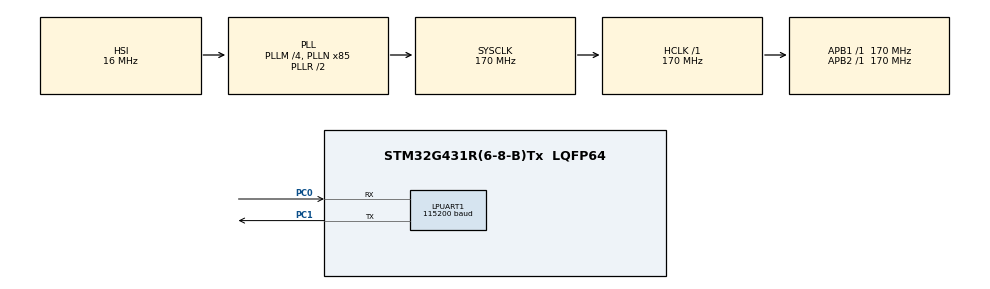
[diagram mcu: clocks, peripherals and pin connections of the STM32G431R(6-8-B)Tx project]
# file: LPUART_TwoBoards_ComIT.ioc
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LPUART1.BaudRate=115200
LPUART1.ClockPrescaler=UART_PRESCALER_DIV1
LPUART1.DMADisableonRxErrorParam=UART_ADVFEATURE_DMA_ENABLEONRXERROR
LPUART1.DataInvertParam=UART_ADVFEATURE_DATAINV_DISABLE
LPUART1.FIFOMode=UART_FIFOMODE_DISABLE
LPUART1.MSBFirstParam=UART_ADVFEATURE_MSBFIRST_DISABLE
LPUART1.Mode=UART_MODE_TX_RX
LPUART1.OneBitSampling=UART_ONE_BIT_SAMPLE_DISABLE
LPUART1.OverrunDisableParam=UART_ADVFEATURE_OVERRUN_ENABLE
LPUART1.Parity=UART_PARITY_NONE
LPUART1.RXFIFOThreshold=UART_RXFIFO_THRESHOLD_1_8
LPUART1.RxPinLevelInvertParam=UART_ADVFEATURE_RXINV_DISABLE
LPUART1.StopBits=UART_STOPBITS_1
LPUART1.SwapParam=UART_ADVFEATURE_SWAP_DISABLE
LPUART1.TXFIFOThreshold=UART_TXFIFO_THRESHOLD_1_8
LPUART1.TxPinLevelInvertParam=UART_ADVFEATURE_TXINV_DISABLE
LPUART1.WordLength=UART_WORDLENGTH_8B
Mcu.Family=STM32G4
Mcu.Name=STM32G431R(6-8-B)Tx
Mcu.Package=LQFP64
NVIC.LPUART1_IRQn=true\:1\:0\:true\:false\:true\:true\:true\:true
NVIC.PriorityGroup=NVIC_PRIORITYGROUP_4
PC0.GPIO_PuPd=GPIO_PULLUP
PC0.GPIO_Speed=GPIO_SPEED_FREQ_HIGH
PC0.Mode=Asynchronous
PC0.Signal=LPUART1_RX
PC1.GPIO_PuPd=GPIO_PULLUP
PC1.GPIO_Speed=GPIO_SPEED_FREQ_HIGH
PC1.Mode=Asynchronous
PC1.Signal=LPUART1_TX
ProjectManager.HeapSize=0x200
ProjectManager.StackSize=0x400
ProjectManager.TargetToolchain=EWARM V8.32
RCC.ADC12Freq_Value=170000000
RCC.AHBFreq_Value=170000000
RCC.APB1Freq_Value=170000000
RCC.APB1TimFreq_Value=170000000
RCC.APB2Freq_Value=170000000
RCC.APB2TimFreq_Value=170000000
RCC.CortexFreq_Value=170000000
RCC.EXTERNAL_CLOCK_VALUE=12288000
RCC.HCLKFreq_Value=170000000
RCC.HSE_VALUE=24000000
RCC.HSI48_VALUE=48000000
RCC.HSI_VALUE=16000000
RCC.LPUART1CLockSelection=RCC_LPUART1CLKSOURCE_HSI
RCC.LSE_VALUE=32768
RCC.PLLM=RCC_PLLM_DIV4
RCC.PLLN=85
RCC.SYSCLKFreq_VALUE=170000000
RCC.SYSCLKSource=RCC_SYSCLKSOURCE_PLLCLK
RCC.UART4CLockSelection=RCC_UART4CLKSOURCE_HSI
RCC.USART1CLockSelection=RCC_USART1CLKSOURCE_HSI
RCC.USART2CLockSelection=RCC_USART2CLKSOURCE_HSI
RCC.USART3CLockSelection=RCC_USART3CLKSOURCE_HSI
RCC.USBFreq_Value=170000000
RCC.VCOOutputFreq_Value=340000000
VP_SYS_VS_DBSignals.Mode=DisableDeadBatterySignals
board=custom

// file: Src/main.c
/* USER CODE BEGIN Header */
/**
  ******************************************************************************
  * @file    UART/LPUART_TwoBoards_ComIT/Src/main.c
  * @author  MCD Application Team
  * @brief   This sample code shows how to use LPUART HAL API to transmit
  *          and receive a data buffer with a communication process based on
  *          IT transfer.
  *          The communication is done using 2 Boards.
  ******************************************************************************
  * @attention
  *
  * <h2><center>&copy; Copyright (c) 2019 STMicroelectronics.
  * All rights reserved.</center></h2>
  *
  * This software component is licensed by ST under BSD 3-Clause license,
  * the "License"; You may not use this file except in compliance with the
  * License. You may obtain a copy of the License at:
  *                        opensource.org/licenses/BSD-3-Clause
  *
  ******************************************************************************
  */
/* USER CODE END Header */
#include "main.h"

/* USER CODE BEGIN Includes */
#include "stm32g4xx_nucleo.h"
/* USER CODE END Includes */

/* USER CODE BEGIN PD */
//#define TRANSMITTER_BOARD
/* USER CODE END PD */

UART_HandleTypeDef hlpuart1;

/* USER CODE BEGIN PV */
/* UART IT status */
__IO ITStatus UartReady = RESET;
__IO ITStatus UartError = RESET;

/* Buffer used for transmission */
uint8_t aTxBuffer[] = " ****LPUART_TwoBoards_ComIT****  ****LPUART_TwoBoards_ComIT****  ****LPUART_TwoBoards_ComIT**** ";

/* Buffer used for reception */
uint8_t aRxBuffer[RXBUFFERSIZE];
/* USER CODE END PV */

void SystemClock_Config(void);
static void MX_GPIO_Init(void);
static void MX_LPUART1_UART_Init(void);
/* USER CODE BEGIN PFP */
static uint16_t Buffercmp(uint8_t* pBuffer1, uint8_t* pBuffer2, uint16_t BufferLength);
/* USER CODE END PFP */

int main(void)
{
  /* USER CODE BEGIN 1 */

  /* STM32G4xx HAL library initialization:
       - Configure the Flash prefetch
       - Systick timer is configured by default as source of time base, but user
         can eventually implement his proper time base source (a general purpose
         timer for example or other time source), keeping in mind that Time base
         duration should be kept 1ms since PPP_TIMEOUT_VALUEs are defined and
         handled in milliseconds basis.
       - Set NVIC Group Priority to 4
       - Low Level Initialization
     */
  /* USER CODE END 1 */

  /* MCU Configuration--------------------------------------------------------*/

  /* Reset of all peripherals, Initializes the Flash interface and the Systick. */
  HAL_Init();

  /* Configure the system clock */
  SystemClock_Config();

  /* USER CODE BEGIN SysInit */
  /* Configure LED2 */
  BSP_LED_Init(LED2);
  /* USER CODE END SysInit */

  /* Initialize all configured peripherals */
  MX_GPIO_Init();
  MX_LPUART1_UART_Init();
  /* USER CODE BEGIN 2 */

#ifdef TRANSMITTER_BOARD

  /* Configure User push-button */
  BSP_PB_Init(BUTTON_USER, BUTTON_MODE_GPIO);

  /* Toggle LED2 waiting for user to press button */
  BSP_LED_On(LED2);

  /* Wait for User push-button press before starting the Communication */
  while (BSP_PB_GetState(BUTTON_USER) != GPIO_PIN_SET)
  {
  }

  /* Wait for User push-button release before starting the Communication */
  while (BSP_PB_GetState(BUTTON_USER) != GPIO_PIN_RESET)
  {
  }

  /* Turn LED2 off */
  BSP_LED_Off(LED2);

  /* Flush the data registers from unexpected data */
  __HAL_UART_FLUSH_DRREGISTER(&hlpuart1);

  /* The board sends the message and expects to receive it back */

  /*##-1- Start the transmission process #####################################*/
  /* While the LPUART in reception process, user can transmit data through
     "aTxBuffer" buffer */
  if(HAL_UART_Transmit_IT(&hlpuart1, (uint8_t*)aTxBuffer, TXBUFFERSIZE)!= HAL_OK)
  {
    Error_Handler();
  }

  /*##-2- Wait for the end of the transfer ###################################*/
  while ((UartReady != SET)&&(UartError != SET))
  {
  }

  /* Check there was no error */
  if(UartError == SET)
  {
    Error_Handler();
  }

  /* Reset transmission flag */
  UartReady = RESET;

  /*##-3- Put LPUART peripheral in reception process #########################*/
  if(HAL_UART_Receive_IT(&hlpuart1, (uint8_t *)aRxBuffer, RXBUFFERSIZE) != HAL_OK)
  {
    Error_Handler();
  }

#else

  /* The board receives the message and sends it back */

  /*##-1- Put LPUART peripheral in reception process #########################*/
  if(HAL_UART_Receive_IT(&hlpuart1, (uint8_t *)aRxBuffer, RXBUFFERSIZE) != HAL_OK)
  {
    Error_Handler();
  }

  /*##-2- Wait for the end of the transfer ###################################*/
  while ((UartReady != SET)&&(UartError != SET))
  {
  }

  /* Check there was no error */
  if(UartError == SET)
  {
    Error_Handler();
  }

  /* Reset transmission flag */
  UartReady = RESET;

  /* Wait some ms for synchronization */
  HAL_Delay(100);

  /*##-3- Start the transmission process #####################################*/
  /* While the LPUART in reception process, user can transmit data through
     "aTxBuffer" buffer */
  if(HAL_UART_Transmit_IT(&hlpuart1, (uint8_t*)aTxBuffer, TXBUFFERSIZE)!= HAL_OK)
  {
    Error_Handler();
  }

#endif /* TRANSMITTER_BOARD */

  /*##-4- Wait for the end of the transfer ###################################*/
  while ((UartReady != SET)&&(UartError != SET))
  {
  }

  /* Check there was no error */
  if(UartError == SET)
  {
    Error_Handler();
  }

  /* Reset transmission flag */
  UartReady = RESET;

  /*##-5- Compare the sent and received buffers ##############################*/
  if(Buffercmp((uint8_t*)aTxBuffer,(uint8_t*)aRxBuffer,RXBUFFERSIZE))
  {
    Error_Handler();
  }

  /* Turn LED2 on: Transfer process is correct */
  BSP_LED_On(LED2);

  /* USER CODE END 2 */

  /* Infinite loop */
  while (1)
  {

  }
}

void SystemClock_Config(void)
{
  RCC_OscInitTypeDef RCC_OscInitStruct = {0};
  RCC_ClkInitTypeDef RCC_ClkInitStruct = {0};
  RCC_PeriphCLKInitTypeDef PeriphClkInit = {0};

  /** Configure the main internal regulator output voltage
  */
  HAL_PWREx_ControlVoltageScaling(PWR_REGULATOR_VOLTAGE_SCALE1_BOOST);
  /** Initializes the RCC Oscillators according to the specified parameters
  * in the RCC_OscInitTypeDef structure.
  */
  RCC_OscInitStruct.OscillatorType = RCC_OSCILLATORTYPE_HSI;
  RCC_OscInitStruct.HSIState = RCC_HSI_ON;
  RCC_OscInitStruct.HSICalibrationValue = RCC_HSICALIBRATION_DEFAULT;
  RCC_OscInitStruct.PLL.PLLState = RCC_PLL_ON;
  RCC_OscInitStruct.PLL.PLLSource = RCC_PLLSOURCE_HSI;
  RCC_OscInitStruct.PLL.PLLM = RCC_PLLM_DIV4;
  RCC_OscInitStruct.PLL.PLLN = 85;
  RCC_OscInitStruct.PLL.PLLP = RCC_PLLP_DIV2;
  RCC_OscInitStruct.PLL.PLLQ = RCC_PLLQ_DIV2;
  RCC_OscInitStruct.PLL.PLLR = RCC_PLLR_DIV2;
  if (HAL_RCC_OscConfig(&RCC_OscInitStruct) != HAL_OK)
  {
    Error_Handler();
  }
  /** Initializes the CPU, AHB and APB buses clocks
  */
  RCC_ClkInitStruct.ClockType = RCC_CLOCKTYPE_HCLK|RCC_CLOCKTYPE_SYSCLK
                              |RCC_CLOCKTYPE_PCLK1|RCC_CLOCKTYPE_PCLK2;
  RCC_ClkInitStruct.SYSCLKSource = RCC_SYSCLKSOURCE_PLLCLK;
  RCC_ClkInitStruct.AHBCLKDivider = RCC_SYSCLK_DIV1;
  RCC_ClkInitStruct.APB1CLKDivider = RCC_HCLK_DIV1;
  RCC_ClkInitStruct.APB2CLKDivider = RCC_HCLK_DIV1;

  if (HAL_RCC_ClockConfig(&RCC_ClkInitStruct, FLASH_LATENCY_4) != HAL_OK)
  {
    Error_Handler();
  }
  /** Initializes the peripherals clocks
  */
  PeriphClkInit.PeriphClockSelection = RCC_PERIPHCLK_LPUART1;
  PeriphClkInit.Lpuart1ClockSelection = RCC_LPUART1CLKSOURCE_HSI;
  if (HAL_RCCEx_PeriphCLKConfig(&PeriphClkInit) != HAL_OK)
  {
    Error_Handler();
  }
}

static void MX_LPUART1_UART_Init(void)
{

  hlpuart1.Instance = LPUART1;
  hlpuart1.Init.BaudRate = 115200;
  hlpuart1.Init.WordLength = UART_WORDLENGTH_8B;
  hlpuart1.Init.StopBits = UART_STOPBITS_1;
  hlpuart1.Init.Parity = UART_PARITY_NONE;
  hlpuart1.Init.Mode = UART_MODE_TX_RX;
  hlpuart1.Init.HwFlowCtl = UART_HWCONTROL_NONE;
  hlpuart1.Init.OneBitSampling = UART_ONE_BIT_SAMPLE_DISABLE;
  hlpuart1.Init.ClockPrescaler = UART_PRESCALER_DIV1;
  hlpuart1.AdvancedInit.AdvFeatureInit = UART_ADVFEATURE_NO_INIT;
  if (HAL_UART_Init(&hlpuart1) != HAL_OK)
  {
    Error_Handler();
  }
  if (HAL_UARTEx_SetTxFifoThreshold(&hlpuart1, UART_TXFIFO_THRESHOLD_1_8) != HAL_OK)
  {
    Error_Handler();
  }
  if (HAL_UARTEx_SetRxFifoThreshold(&hlpuart1, UART_RXFIFO_THRESHOLD_1_8) != HAL_OK)
  {
    Error_Handler();
  }
  if (HAL_UARTEx_DisableFifoMode(&hlpuart1) != HAL_OK)
  {
    Error_Handler();
  }

}

static void MX_GPIO_Init(void)
{

  /* GPIO Ports Clock Enable */
  __HAL_RCC_GPIOC_CLK_ENABLE();

}

/* USER CODE BEGIN 4 */
/**
  * @brief  Tx Transfer completed callback
  * @param  UartHandle: UART handle.
  * @note   This example shows a simple way to report end of IT Tx transfer, and
  *         you can add your own implementation.
  * @retval None
  */
void HAL_UART_TxCpltCallback(UART_HandleTypeDef *UartHandle)
{
  /* Set transmission flag: transfer complete */
  UartReady = SET;
}

/**
  * @brief  Rx Transfer completed callback
  * @param  UartHandle: UART handle
  * @note   This example shows a simple way to report end of IT Rx transfer, and
  *         you can add your own implementation.
  * @retval None
  */
void HAL_UART_RxCpltCallback(UART_HandleTypeDef *UartHandle)
{
  /* Set transmission flag: transfer complete */
  UartReady = SET;
}

/**
  * @brief  UART error callbacks
  * @param  UartHandle: UART handle
  * @note   This example shows a simple way to report transfer error, and you can
  *         add your own implementation.
  * @retval None
  */
void HAL_UART_ErrorCallback(UART_HandleTypeDef *UartHandle)
{
  /* Set error flag */
  UartError = SET;
}

/**
  * @brief  Compares two buffers.
  * @param  pBuffer1, pBuffer2: buffers to be compared.
  * @param  BufferLength: buffer's length
  * @retval 0  : pBuffer1 identical to pBuffer2
  *         >0 : pBuffer1 differs from pBuffer2
  */
static uint16_t Buffercmp(uint8_t* pBuffer1, uint8_t* pBuffer2, uint16_t BufferLength)
{
  while (BufferLength--)
  {
    if ((*pBuffer1) != *pBuffer2)
    {
      return BufferLength;
    }
    pBuffer1++;
    pBuffer2++;
  }

  return 0;
}
/* USER CODE END 4 */

void Error_Handler(void)
{
  /* USER CODE BEGIN Error_Handler_Debug */
  /* User can add his own implementation to report the HAL error return state */
  while(1)
  {
    /* Error if LED2 is slowly blinking (1 sec. period) */
    BSP_LED_Toggle(LED2);
    HAL_Delay(1000);
  }
  /* USER CODE END Error_Handler_Debug */
}

/************************ (C) COPYRIGHT STMicroelectronics *****END OF FILE****/
